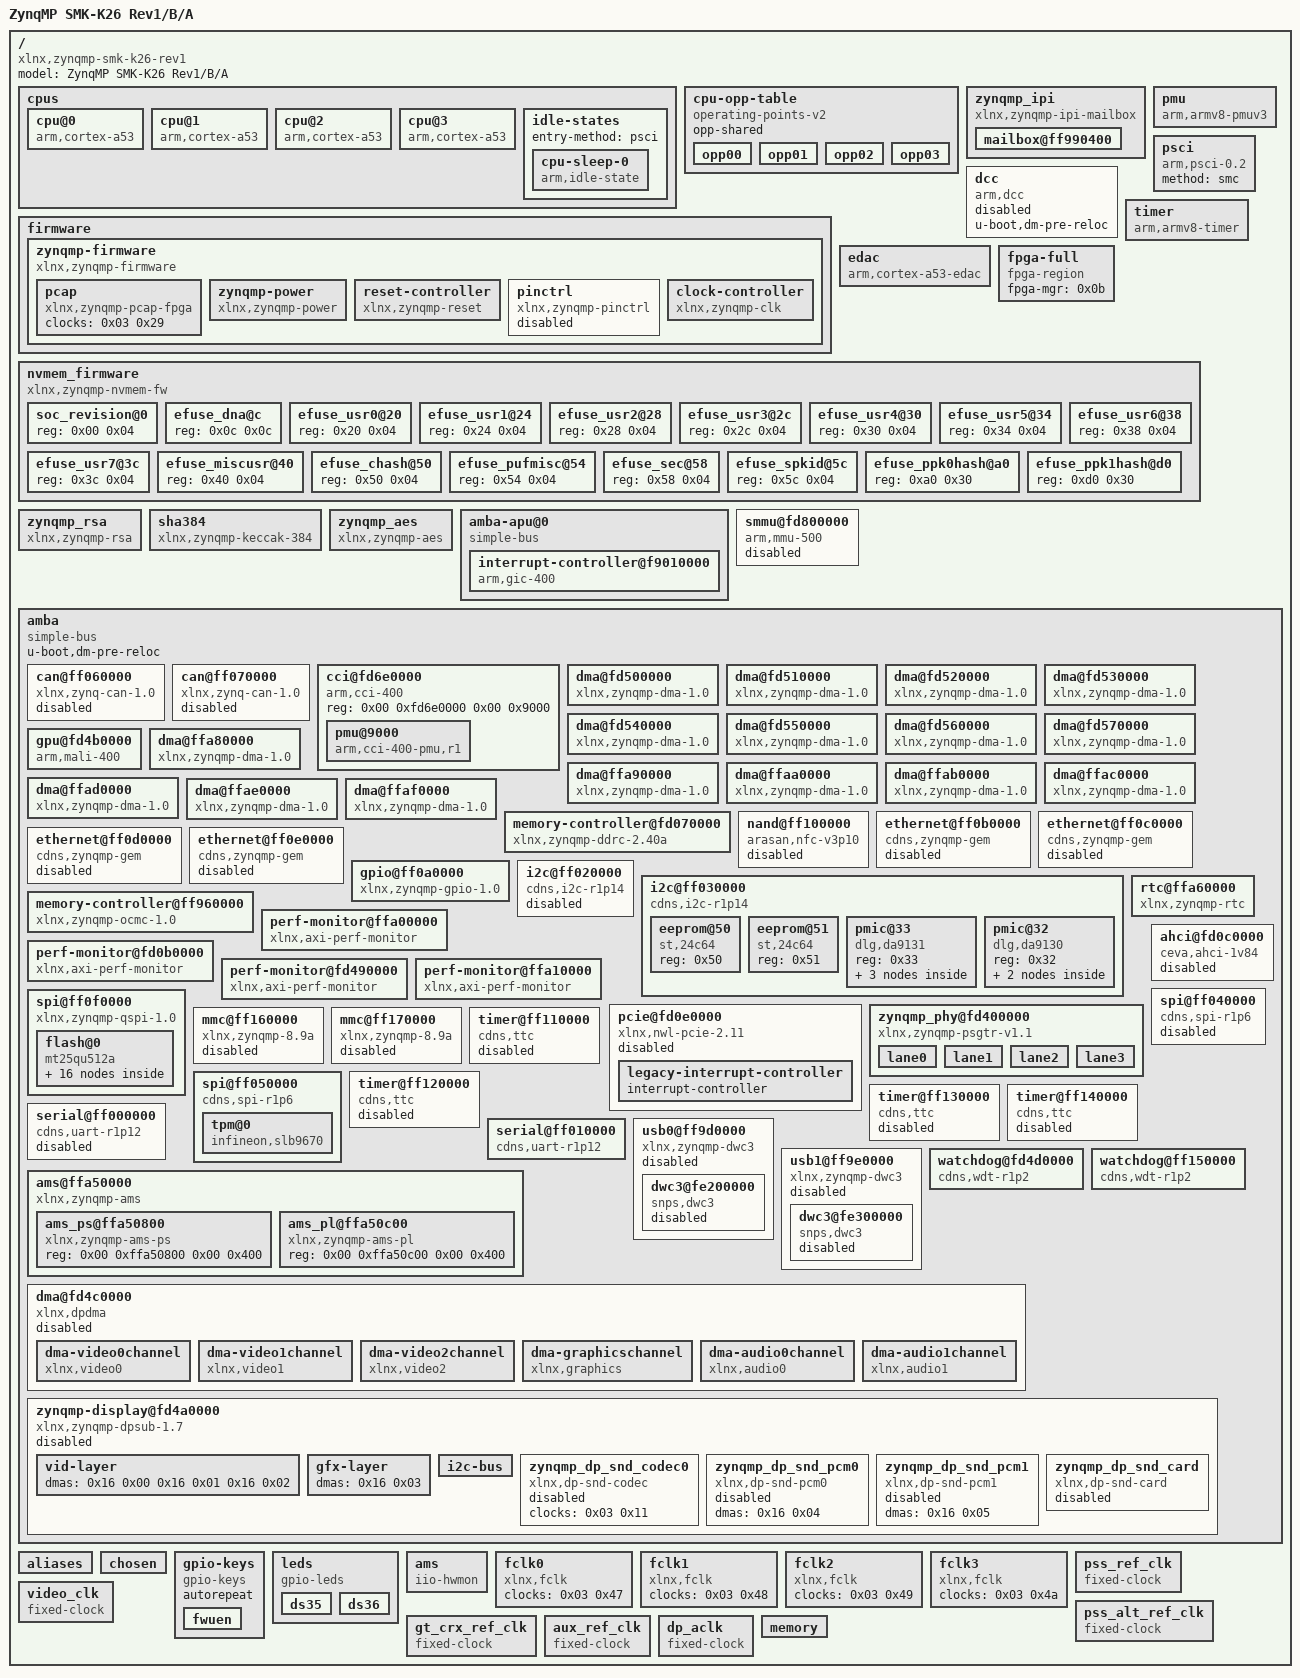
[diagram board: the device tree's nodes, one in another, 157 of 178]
// SPDX-License-Identifier: GPL-2.0
/*
 * KV260 Base Linux DTS
 *
 * (C) Copyright 2021, Xilinx, Inc.
 *
 * amit nagal <amitn@xilinx.com>
 * swagath gadde <swagath.gadde@xilinx.com>
*/

/dts-v1/;

/ {
	compatible = "xlnx,zynqmp-smk-k26-rev1\0xlnx,zynqmp-smk-k26-revB\0xlnx,zynqmp-smk-k26-revA\0xlnx,zynqmp-smk-k26\0xlnx,zynqmp";
	#address-cells = <0x02>;
	#size-cells = <0x02>;
	model = "ZynqMP SMK-K26 Rev1/B/A";

	cpus {
		#address-cells = <0x01>;
		#size-cells = <0x00>;

		cpu@0 {
			compatible = "arm,cortex-a53";
			device_type = "cpu";
			enable-method = "psci";
			operating-points-v2 = <0x01>;
			reg = <0x00>;
			cpu-idle-states = <0x02>;
			clocks = <0x03 0x0a>;
			phandle = <0x1b>;
		};

		cpu@1 {
			compatible = "arm,cortex-a53";
			device_type = "cpu";
			enable-method = "psci";
			reg = <0x01>;
			operating-points-v2 = <0x01>;
			cpu-idle-states = <0x02>;
			phandle = <0x1c>;
		};

		cpu@2 {
			compatible = "arm,cortex-a53";
			device_type = "cpu";
			enable-method = "psci";
			reg = <0x02>;
			operating-points-v2 = <0x01>;
			cpu-idle-states = <0x02>;
			phandle = <0x1d>;
		};

		cpu@3 {
			compatible = "arm,cortex-a53";
			device_type = "cpu";
			enable-method = "psci";
			reg = <0x03>;
			operating-points-v2 = <0x01>;
			cpu-idle-states = <0x02>;
			phandle = <0x1e>;
		};

		idle-states {
			entry-method = "psci";

			cpu-sleep-0 {
				compatible = "arm,idle-state";
				arm,psci-suspend-param = <0x40000000>;
				local-timer-stop;
				entry-latency-us = <0x12c>;
				exit-latency-us = <0x258>;
				min-residency-us = <0x2710>;
				phandle = <0x02>;
			};
		};
	};

	cpu-opp-table {
		compatible = "operating-points-v2";
		opp-shared;
		phandle = <0x01>;

		opp00 {
			opp-hz = <0x00 0x47868bf4>;
			opp-microvolt = <0xf4240>;
			clock-latency-ns = <0x7a120>;
		};

		opp01 {
			opp-hz = <0x00 0x23c345fa>;
			opp-microvolt = <0xf4240>;
			clock-latency-ns = <0x7a120>;
		};

		opp02 {
			opp-hz = <0x00 0x17d783fc>;
			opp-microvolt = <0xf4240>;
			clock-latency-ns = <0x7a120>;
		};

		opp03 {
			opp-hz = <0x00 0x11e1a2fd>;
			opp-microvolt = <0xf4240>;
			clock-latency-ns = <0x7a120>;
		};
	};

	zynqmp_ipi {
		u-boot,dm-pre-reloc;
		compatible = "xlnx,zynqmp-ipi-mailbox";
		interrupt-parent = <0x04>;
		interrupts = <0x00 0x23 0x04>;
		xlnx,ipi-id = <0x00>;
		#address-cells = <0x02>;
		#size-cells = <0x02>;
		ranges;

		mailbox@ff990400 {
			u-boot,dm-pre-reloc;
			reg = <0x00 0xff9905c0 0x00 0x20 0x00 0xff9905e0 0x00 0x20 0x00 0xff990e80 0x00 0x20 0x00 0xff990ea0 0x00 0x20>;
			reg-names = "local_request_region\0local_response_region\0remote_request_region\0remote_response_region";
			#mbox-cells = <0x01>;
			xlnx,ipi-id = <0x04>;
			phandle = <0x05>;
		};
	};

	dcc {
		compatible = "arm,dcc";
		status = "disabled";
		u-boot,dm-pre-reloc;
		phandle = <0x1f>;
	};

	pmu {
		compatible = "arm,armv8-pmuv3";
		interrupt-parent = <0x04>;
		interrupts = <0x00 0x8f 0x04 0x00 0x90 0x04 0x00 0x91 0x04 0x00 0x92 0x04>;
	};

	psci {
		compatible = "arm,psci-0.2";
		method = "smc";
	};

	firmware {

		zynqmp-firmware {
			compatible = "xlnx,zynqmp-firmware";
			u-boot,dm-pre-reloc;
			method = "smc";
			#power-domain-cells = <0x01>;
			phandle = <0x0c>;

			pcap {
				compatible = "xlnx,zynqmp-pcap-fpga";
				clock-names = "ref_clk";
				clocks = <0x03 0x29>;
				phandle = <0x0b>;
			};

			zynqmp-power {
				u-boot,dm-pre-reloc;
				compatible = "xlnx,zynqmp-power";
				interrupt-parent = <0x04>;
				interrupts = <0x00 0x23 0x04>;
				mboxes = <0x05 0x00 0x05 0x01>;
				mbox-names = "tx\0rx";
				phandle = <0x20>;
			};

			reset-controller {
				compatible = "xlnx,zynqmp-reset";
				#reset-cells = <0x01>;
				phandle = <0x12>;
			};

			pinctrl {
				compatible = "xlnx,zynqmp-pinctrl";
				status = "disabled";
				phandle = <0x21>;
			};

			clock-controller {
				u-boot,dm-pre-reloc;
				#clock-cells = <0x01>;
				compatible = "xlnx,zynqmp-clk";
				clocks = <0x06 0x07 0x08 0x09 0x0a>;
				clock-names = "pss_ref_clk\0video_clk\0pss_alt_ref_clk\0aux_ref_clk\0gt_crx_ref_clk";
				phandle = <0x03>;
			};
		};
	};

	timer {
		compatible = "arm,armv8-timer";
		interrupt-parent = <0x04>;
		interrupts = <0x01 0x0d 0xf08 0x01 0x0e 0xf08 0x01 0x0b 0xf08 0x01 0x0a 0xf08>;
	};

	edac {
		compatible = "arm,cortex-a53-edac";
	};

	fpga-full {
		compatible = "fpga-region";
		fpga-mgr = <0x0b>;
		#address-cells = <0x02>;
		#size-cells = <0x02>;
		ranges;
		phandle = <0x22>;
	};

	nvmem_firmware {
		compatible = "xlnx,zynqmp-nvmem-fw";
		#address-cells = <0x01>;
		#size-cells = <0x01>;

		soc_revision@0 {
			reg = <0x00 0x04>;
			phandle = <0x11>;
		};

		efuse_dna@c {
			reg = <0x0c 0x0c>;
			phandle = <0x23>;
		};

		efuse_usr0@20 {
			reg = <0x20 0x04>;
			phandle = <0x24>;
		};

		efuse_usr1@24 {
			reg = <0x24 0x04>;
			phandle = <0x25>;
		};

		efuse_usr2@28 {
			reg = <0x28 0x04>;
			phandle = <0x26>;
		};

		efuse_usr3@2c {
			reg = <0x2c 0x04>;
			phandle = <0x27>;
		};

		efuse_usr4@30 {
			reg = <0x30 0x04>;
			phandle = <0x28>;
		};

		efuse_usr5@34 {
			reg = <0x34 0x04>;
			phandle = <0x29>;
		};

		efuse_usr6@38 {
			reg = <0x38 0x04>;
			phandle = <0x2a>;
		};

		efuse_usr7@3c {
			reg = <0x3c 0x04>;
			phandle = <0x2b>;
		};

		efuse_miscusr@40 {
			reg = <0x40 0x04>;
			phandle = <0x2c>;
		};

		efuse_chash@50 {
			reg = <0x50 0x04>;
			phandle = <0x2d>;
		};

		efuse_pufmisc@54 {
			reg = <0x54 0x04>;
			phandle = <0x2e>;
		};

		efuse_sec@58 {
			reg = <0x58 0x04>;
			phandle = <0x2f>;
		};

		efuse_spkid@5c {
			reg = <0x5c 0x04>;
			phandle = <0x30>;
		};

		efuse_ppk0hash@a0 {
			reg = <0xa0 0x30>;
			phandle = <0x31>;
		};

		efuse_ppk1hash@d0 {
			reg = <0xd0 0x30>;
			phandle = <0x32>;
		};
	};

	zynqmp_rsa {
		compatible = "xlnx,zynqmp-rsa";
		phandle = <0x33>;
	};

	sha384 {
		compatible = "xlnx,zynqmp-keccak-384";
		phandle = <0x34>;
	};

	zynqmp_aes {
		compatible = "xlnx,zynqmp-aes";
		phandle = <0x35>;
	};

	amba-apu@0 {
		compatible = "simple-bus";
		#address-cells = <0x02>;
		#size-cells = <0x01>;
		ranges = <0x00 0x00 0x00 0x00 0xffffffff>;
		phandle = <0x36>;

		interrupt-controller@f9010000 {
			compatible = "arm,gic-400";
			#interrupt-cells = <0x03>;
			reg = <0x00 0xf9010000 0x10000 0x00 0xf9020000 0x20000 0x00 0xf9040000 0x20000 0x00 0xf9060000 0x20000>;
			interrupt-controller;
			interrupt-parent = <0x04>;
			interrupts = <0x01 0x09 0xf04>;
			num_cpus = <0x02>;
			num_interrupts = <0x60>;
			phandle = <0x04>;
		};
	};

	smmu@fd800000 {
		compatible = "arm,mmu-500";
		reg = <0x00 0xfd800000 0x00 0x20000>;
		#iommu-cells = <0x01>;
		status = "disabled";
		#global-interrupts = <0x01>;
		interrupt-parent = <0x04>;
		interrupts = <0x00 0x9b 0x04 0x00 0x9b 0x04 0x00 0x9b 0x04 0x00 0x9b 0x04 0x00 0x9b 0x04 0x00 0x9b 0x04 0x00 0x9b 0x04 0x00 0x9b 0x04 0x00 0x9b 0x04 0x00 0x9b 0x04 0x00 0x9b 0x04 0x00 0x9b 0x04 0x00 0x9b 0x04 0x00 0x9b 0x04 0x00 0x9b 0x04 0x00 0x9b 0x04 0x00 0x9b 0x04>;
		phandle = <0x0d>;
	};

	amba {
		compatible = "simple-bus";
		u-boot,dm-pre-reloc;
		#address-cells = <0x02>;
		#size-cells = <0x02>;
		ranges;
		phandle = <0x37>;

		can@ff060000 {
			compatible = "xlnx,zynq-can-1.0";
			status = "disabled";
			clock-names = "can_clk\0pclk";
			reg = <0x00 0xff060000 0x00 0x1000>;
			interrupts = <0x00 0x17 0x04>;
			interrupt-parent = <0x04>;
			tx-fifo-depth = <0x40>;
			rx-fifo-depth = <0x40>;
			power-domains = <0x0c 0x2f>;
			clocks = <0x03 0x3f 0x03 0x1f>;
			phandle = <0x38>;
		};

		can@ff070000 {
			compatible = "xlnx,zynq-can-1.0";
			status = "disabled";
			clock-names = "can_clk\0pclk";
			reg = <0x00 0xff070000 0x00 0x1000>;
			interrupts = <0x00 0x18 0x04>;
			interrupt-parent = <0x04>;
			tx-fifo-depth = <0x40>;
			rx-fifo-depth = <0x40>;
			power-domains = <0x0c 0x30>;
			clocks = <0x03 0x40 0x03 0x1f>;
			phandle = <0x39>;
		};

		cci@fd6e0000 {
			compatible = "arm,cci-400";
			status = "okay";
			reg = <0x00 0xfd6e0000 0x00 0x9000>;
			ranges = <0x00 0x00 0xfd6e0000 0x10000>;
			#address-cells = <0x01>;
			#size-cells = <0x01>;
			phandle = <0x3a>;

			pmu@9000 {
				compatible = "arm,cci-400-pmu,r1";
				reg = <0x9000 0x5000>;
				interrupt-parent = <0x04>;
				interrupts = <0x00 0x7b 0x04 0x00 0x7b 0x04 0x00 0x7b 0x04 0x00 0x7b 0x04 0x00 0x7b 0x04>;
			};
		};

		dma@fd500000 {
			status = "okay";
			compatible = "xlnx,zynqmp-dma-1.0";
			reg = <0x00 0xfd500000 0x00 0x1000>;
			interrupt-parent = <0x04>;
			interrupts = <0x00 0x7c 0x04>;
			clock-names = "clk_main\0clk_apb";
			xlnx,bus-width = <0x80>;
			#stream-id-cells = <0x01>;
			iommus = <0x0d 0x14e8>;
			power-domains = <0x0c 0x2a>;
			clocks = <0x03 0x13 0x03 0x1f>;
			phandle = <0x3b>;
		};

		dma@fd510000 {
			status = "okay";
			compatible = "xlnx,zynqmp-dma-1.0";
			reg = <0x00 0xfd510000 0x00 0x1000>;
			interrupt-parent = <0x04>;
			interrupts = <0x00 0x7d 0x04>;
			clock-names = "clk_main\0clk_apb";
			xlnx,bus-width = <0x80>;
			#stream-id-cells = <0x01>;
			iommus = <0x0d 0x14e9>;
			power-domains = <0x0c 0x2a>;
			clocks = <0x03 0x13 0x03 0x1f>;
			phandle = <0x3c>;
		};

		dma@fd520000 {
			status = "okay";
			compatible = "xlnx,zynqmp-dma-1.0";
			reg = <0x00 0xfd520000 0x00 0x1000>;
			interrupt-parent = <0x04>;
			interrupts = <0x00 0x7e 0x04>;
			clock-names = "clk_main\0clk_apb";
			xlnx,bus-width = <0x80>;
			#stream-id-cells = <0x01>;
			iommus = <0x0d 0x14ea>;
			power-domains = <0x0c 0x2a>;
			clocks = <0x03 0x13 0x03 0x1f>;
			phandle = <0x3d>;
		};

		dma@fd530000 {
			status = "okay";
			compatible = "xlnx,zynqmp-dma-1.0";
			reg = <0x00 0xfd530000 0x00 0x1000>;
			interrupt-parent = <0x04>;
			interrupts = <0x00 0x7f 0x04>;
			clock-names = "clk_main\0clk_apb";
			xlnx,bus-width = <0x80>;
			#stream-id-cells = <0x01>;
			iommus = <0x0d 0x14eb>;
			power-domains = <0x0c 0x2a>;
			clocks = <0x03 0x13 0x03 0x1f>;
			phandle = <0x3e>;
		};

		dma@fd540000 {
			status = "okay";
			compatible = "xlnx,zynqmp-dma-1.0";
			reg = <0x00 0xfd540000 0x00 0x1000>;
			interrupt-parent = <0x04>;
			interrupts = <0x00 0x80 0x04>;
			clock-names = "clk_main\0clk_apb";
			xlnx,bus-width = <0x80>;
			#stream-id-cells = <0x01>;
			iommus = <0x0d 0x14ec>;
			power-domains = <0x0c 0x2a>;
			clocks = <0x03 0x13 0x03 0x1f>;
			phandle = <0x3f>;
		};

		dma@fd550000 {
			status = "okay";
			compatible = "xlnx,zynqmp-dma-1.0";
			reg = <0x00 0xfd550000 0x00 0x1000>;
			interrupt-parent = <0x04>;
			interrupts = <0x00 0x81 0x04>;
			clock-names = "clk_main\0clk_apb";
			xlnx,bus-width = <0x80>;
			#stream-id-cells = <0x01>;
			iommus = <0x0d 0x14ed>;
			power-domains = <0x0c 0x2a>;
			clocks = <0x03 0x13 0x03 0x1f>;
			phandle = <0x40>;
		};

		dma@fd560000 {
			status = "okay";
			compatible = "xlnx,zynqmp-dma-1.0";
			reg = <0x00 0xfd560000 0x00 0x1000>;
			interrupt-parent = <0x04>;
			interrupts = <0x00 0x82 0x04>;
			clock-names = "clk_main\0clk_apb";
			xlnx,bus-width = <0x80>;
			#stream-id-cells = <0x01>;
			iommus = <0x0d 0x14ee>;
			power-domains = <0x0c 0x2a>;
			clocks = <0x03 0x13 0x03 0x1f>;
			phandle = <0x41>;
		};

		dma@fd570000 {
			status = "okay";
			compatible = "xlnx,zynqmp-dma-1.0";
			reg = <0x00 0xfd570000 0x00 0x1000>;
			interrupt-parent = <0x04>;
			interrupts = <0x00 0x83 0x04>;
			clock-names = "clk_main\0clk_apb";
			xlnx,bus-width = <0x80>;
			#stream-id-cells = <0x01>;
			iommus = <0x0d 0x14ef>;
			power-domains = <0x0c 0x2a>;
			clocks = <0x03 0x13 0x03 0x1f>;
			phandle = <0x42>;
		};

		gpu@fd4b0000 {
			status = "okay";
			compatible = "arm,mali-400\0arm,mali-utgard";
			reg = <0x00 0xfd4b0000 0x00 0x10000>;
			interrupt-parent = <0x04>;
			interrupts = <0x00 0x84 0x04 0x00 0x84 0x04 0x00 0x84 0x04 0x00 0x84 0x04 0x00 0x84 0x04 0x00 0x84 0x04>;
			interrupt-names = "IRQGP\0IRQGPMMU\0IRQPP0\0IRQPPMMU0\0IRQPP1\0IRQPPMMU1";
			clock-names = "gpu\0gpu_pp0\0gpu_pp1";
			power-domains = <0x0c 0x3a>;
			clocks = <0x03 0x18 0x03 0x19 0x03 0x1a>;
			xlnx,tz-nonsecure = <0x01>;
			phandle = <0x43>;
		};

		dma@ffa80000 {
			status = "okay";
			compatible = "xlnx,zynqmp-dma-1.0";
			reg = <0x00 0xffa80000 0x00 0x1000>;
			interrupt-parent = <0x04>;
			interrupts = <0x00 0x4d 0x04>;
			clock-names = "clk_main\0clk_apb";
			xlnx,bus-width = <0x40>;
			#stream-id-cells = <0x01>;
			power-domains = <0x0c 0x2b>;
			clocks = <0x03 0x44 0x03 0x1f>;
			phandle = <0x44>;
		};

		dma@ffa90000 {
			status = "okay";
			compatible = "xlnx,zynqmp-dma-1.0";
			reg = <0x00 0xffa90000 0x00 0x1000>;
			interrupt-parent = <0x04>;
			interrupts = <0x00 0x4e 0x04>;
			clock-names = "clk_main\0clk_apb";
			xlnx,bus-width = <0x40>;
			#stream-id-cells = <0x01>;
			power-domains = <0x0c 0x2b>;
			clocks = <0x03 0x44 0x03 0x1f>;
			phandle = <0x45>;
		};

		dma@ffaa0000 {
			status = "okay";
			compatible = "xlnx,zynqmp-dma-1.0";
			reg = <0x00 0xffaa0000 0x00 0x1000>;
			interrupt-parent = <0x04>;
			interrupts = <0x00 0x4f 0x04>;
			clock-names = "clk_main\0clk_apb";
			xlnx,bus-width = <0x40>;
			#stream-id-cells = <0x01>;
			power-domains = <0x0c 0x2b>;
			clocks = <0x03 0x44 0x03 0x1f>;
			phandle = <0x46>;
		};

		dma@ffab0000 {
			status = "okay";
			compatible = "xlnx,zynqmp-dma-1.0";
			reg = <0x00 0xffab0000 0x00 0x1000>;
			interrupt-parent = <0x04>;
			interrupts = <0x00 0x50 0x04>;
			clock-names = "clk_main\0clk_apb";
			xlnx,bus-width = <0x40>;
			#stream-id-cells = <0x01>;
			power-domains = <0x0c 0x2b>;
			clocks = <0x03 0x44 0x03 0x1f>;
			phandle = <0x47>;
		};

		dma@ffac0000 {
			status = "okay";
			compatible = "xlnx,zynqmp-dma-1.0";
			reg = <0x00 0xffac0000 0x00 0x1000>;
			interrupt-parent = <0x04>;
			interrupts = <0x00 0x51 0x04>;
			clock-names = "clk_main\0clk_apb";
			xlnx,bus-width = <0x40>;
			#stream-id-cells = <0x01>;
			power-domains = <0x0c 0x2b>;
			clocks = <0x03 0x44 0x03 0x1f>;
			phandle = <0x48>;
		};

		dma@ffad0000 {
			status = "okay";
			compatible = "xlnx,zynqmp-dma-1.0";
			reg = <0x00 0xffad0000 0x00 0x1000>;
			interrupt-parent = <0x04>;
			interrupts = <0x00 0x52 0x04>;
			clock-names = "clk_main\0clk_apb";
			xlnx,bus-width = <0x40>;
			#stream-id-cells = <0x01>;
			power-domains = <0x0c 0x2b>;
			clocks = <0x03 0x44 0x03 0x1f>;
			phandle = <0x49>;
		};

		dma@ffae0000 {
			status = "okay";
			compatible = "xlnx,zynqmp-dma-1.0";
			reg = <0x00 0xffae0000 0x00 0x1000>;
			interrupt-parent = <0x04>;
			interrupts = <0x00 0x53 0x04>;
			clock-names = "clk_main\0clk_apb";
			xlnx,bus-width = <0x40>;
			#stream-id-cells = <0x01>;
			power-domains = <0x0c 0x2b>;
			clocks = <0x03 0x44 0x03 0x1f>;
			phandle = <0x4a>;
		};

		dma@ffaf0000 {
			status = "okay";
			compatible = "xlnx,zynqmp-dma-1.0";
			reg = <0x00 0xffaf0000 0x00 0x1000>;
			interrupt-parent = <0x04>;
			interrupts = <0x00 0x54 0x04>;
			clock-names = "clk_main\0clk_apb";
			xlnx,bus-width = <0x40>;
			#stream-id-cells = <0x01>;
			power-domains = <0x0c 0x2b>;
			clocks = <0x03 0x44 0x03 0x1f>;
			phandle = <0x4b>;
		};

		memory-controller@fd070000 {
			compatible = "xlnx,zynqmp-ddrc-2.40a";
			reg = <0x00 0xfd070000 0x00 0x30000>;
			interrupt-parent = <0x04>;
			interrupts = <0x00 0x70 0x04>;
			phandle = <0x4c>;
		};

		nand@ff100000 {
			compatible = "arasan,nfc-v3p10";
			status = "disabled";
			reg = <0x00 0xff100000 0x00 0x1000>;
			clock-names = "clk_sys\0clk_flash";
			interrupt-parent = <0x04>;
			interrupts = <0x00 0x0e 0x04>;
			#address-cells = <0x01>;
			#size-cells = <0x00>;
			#stream-id-cells = <0x01>;
			iommus = <0x0d 0x872>;
			power-domains = <0x0c 0x2c>;
			clocks = <0x03 0x3c 0x03 0x1f>;
			phandle = <0x4d>;
		};

		ethernet@ff0b0000 {
			compatible = "cdns,zynqmp-gem\0cdns,gem";
			status = "disabled";
			interrupt-parent = <0x04>;
			interrupts = <0x00 0x39 0x04 0x00 0x39 0x04>;
			reg = <0x00 0xff0b0000 0x00 0x1000>;
			clock-names = "pclk\0hclk\0tx_clk\0rx_clk\0tsu_clk";
			#address-cells = <0x01>;
			#size-cells = <0x00>;
			#stream-id-cells = <0x01>;
			iommus = <0x0d 0x874>;
			power-domains = <0x0c 0x1d>;
			clocks = <0x03 0x1f 0x03 0x68 0x03 0x2d 0x03 0x31 0x03 0x2c>;
			phandle = <0x4e>;
		};

		ethernet@ff0c0000 {
			compatible = "cdns,zynqmp-gem\0cdns,gem";
			status = "disabled";
			interrupt-parent = <0x04>;
			interrupts = <0x00 0x3b 0x04 0x00 0x3b 0x04>;
			reg = <0x00 0xff0c0000 0x00 0x1000>;
			clock-names = "pclk\0hclk\0tx_clk\0rx_clk\0tsu_clk";
			#address-cells = <0x01>;
			#size-cells = <0x00>;
			#stream-id-cells = <0x01>;
			iommus = <0x0d 0x875>;
			power-domains = <0x0c 0x1e>;
			clocks = <0x03 0x1f 0x03 0x69 0x03 0x2e 0x03 0x32 0x03 0x2c>;
			phandle = <0x4f>;
		};

		ethernet@ff0d0000 {
			compatible = "cdns,zynqmp-gem\0cdns,gem";
			status = "disabled";
			interrupt-parent = <0x04>;
			interrupts = <0x00 0x3d 0x04 0x00 0x3d 0x04>;
			reg = <0x00 0xff0d0000 0x00 0x1000>;
			clock-names = "pclk\0hclk\0tx_clk\0rx_clk\0tsu_clk";
			#address-cells = <0x01>;
			#size-cells = <0x00>;
			#stream-id-cells = <0x01>;
			iommus = <0x0d 0x876>;
			power-domains = <0x0c 0x1f>;
			clocks = <0x03 0x1f 0x03 0x6a 0x03 0x2f 0x03 0x33 0x03 0x2c>;
			phandle = <0x50>;
		};

		ethernet@ff0e0000 {
			compatible = "cdns,zynqmp-gem\0cdns,gem";
			status = "disabled";
			interrupt-parent = <0x04>;
			interrupts = <0x00 0x3f 0x04 0x00 0x3f 0x04>;
			reg = <0x00 0xff0e0000 0x00 0x1000>;
			clock-names = "pclk\0hclk\0tx_clk\0rx_clk\0tsu_clk";
			#address-cells = <0x01>;
			#size-cells = <0x00>;
			#stream-id-cells = <0x01>;
			iommus = <0x0d 0x877>;
			power-domains = <0x0c 0x20>;
			clocks = <0x03 0x1f 0x03 0x6b 0x03 0x30 0x03 0x34 0x03 0x2c>;
			phy-mode = "rgmii-id";
			xlnx,ptp-enet-clock = <0x00>;
			local-mac-address = [00 0a 35 00 22 01];
			phandle = <0x51>;
		};

		gpio@ff0a0000 {
			compatible = "xlnx,zynqmp-gpio-1.0";
			status = "okay";
			#gpio-cells = <0x02>;
			gpio-controller;
			interrupt-parent = <0x04>;
			interrupts = <0x00 0x10 0x04>;
			interrupt-controller;
			#interrupt-cells = <0x02>;
			reg = <0x00 0xff0a0000 0x00 0x1000>;
			power-domains = <0x0c 0x2e>;
			gpio-line-names = "QSPI_CLK\0QSPI_DQ1\0QSPI_DQ2\0QSPI_DQ3\0QSPI_DQ0\0QSPI_CS_B\0SPI_CLK\0LED1\0LED2\0SPI_CS_B\0SPI_MISO\0SPI_MOSI\0FWUEN\0EMMC_DAT0\0EMMC_DAT1\0EMMC_DAT2\0EMMC_DAT3\0EMMC_DAT4\0EMMC_DAT5\0EMMC_DAT6\0EMMC_DAT7\0EMMC_CMD\0EMMC_CLK\0EMMC_RST\0I2C1_SCL\0I2C1_SDA\0\0\0\0\0\0\0\0\0\0\0\0\0\0\0\0\0\0\0\0\0\0\0\0\0\0\0\0\0\0\0\0\0\0\0\0\0\0\0\0\0\0\0\0\0\0\0\0\0\0\0\0\0\0\0\0\0\0\0\0\0\0\0\0\0\0\0\0\0\0\0\0\0\0\0\0\0\0\0\0\0\0\0\0\0\0\0\0\0\0\0\0\0\0\0\0\0\0\0\0\0\0\0\0\0\0\0\0\0\0\0\0\0\0\0\0\0\0\0\0\0\0\0\0\0\0\0\0\0\0\0\0\0\0\0\0\0\0\0\0\0\0\0\0\0\0\0\0";
			clocks = <0x03 0x1f>;
			emio-gpio-width = <0x20>;
			gpio-mask-high = <0x00>;
			gpio-mask-low = <0x5600>;
			phandle = <0x0e>;
		};

		i2c@ff020000 {
			compatible = "cdns,i2c-r1p14\0cdns,i2c-r1p10";
			status = "disabled";
			interrupt-parent = <0x04>;
			interrupts = <0x00 0x11 0x04>;
			reg = <0x00 0xff020000 0x00 0x1000>;
			#address-cells = <0x01>;
			#size-cells = <0x00>;
			power-domains = <0x0c 0x25>;
			clocks = <0x03 0x3d>;
			phandle = <0x52>;
		};

		i2c@ff030000 {
			compatible = "cdns,i2c-r1p14\0cdns,i2c-r1p10";
			status = "okay";
			interrupt-parent = <0x04>;
			interrupts = <0x00 0x12 0x04>;
			reg = <0x00 0xff030000 0x00 0x1000>;
			#address-cells = <0x01>;
			#size-cells = <0x00>;
			power-domains = <0x0c 0x26>;
			clock-frequency = <0x61a80>;
			scl-gpios = <0x0e 0x18 0x00>;
			sda-gpios = <0x0e 0x19 0x00>;
			clocks = <0x03 0x3e>;
			phandle = <0x53>;

			eeprom@50 {
				compatible = "st,24c64\0atmel,24c64";
				reg = <0x50>;
				phandle = <0x54>;
			};

			eeprom@51 {
				compatible = "st,24c64\0atmel,24c64";
				reg = <0x51>;
				phandle = <0x55>;
			};

			pmic@33 {
				compatible = "dlg,da9131";
				reg = <0x33>;
				phandle = <0x56>;

				regulators {

					buck1 {
						regulator-name = "da9131_buck1";
						regulator-boot-on;
						regulator-always-on;
						phandle = <0x57>;
					};

					buck2 {
						regulator-name = "da9131_buck2";
						regulator-boot-on;
						regulator-always-on;
						phandle = <0x58>;
					};
				};
			};

			pmic@32 {
				compatible = "dlg,da9130";
				reg = <0x32>;
				phandle = <0x59>;

				regulators {

					buck1 {
						regulator-name = "da9130_buck1";
						regulator-boot-on;
						regulator-always-on;
						phandle = <0x5a>;
					};
				};
			};
		};

		memory-controller@ff960000 {
			compatible = "xlnx,zynqmp-ocmc-1.0";
			reg = <0x00 0xff960000 0x00 0x1000>;
			interrupt-parent = <0x04>;
			interrupts = <0x00 0x0a 0x04>;
			phandle = <0x5b>;
		};

		perf-monitor@ffa00000 {
			compatible = "xlnx,axi-perf-monitor";
			reg = <0x00 0xffa00000 0x00 0x10000>;
			interrupts = <0x00 0x19 0x04>;
			interrupt-parent = <0x04>;
			xlnx,enable-profile = <0x00>;
			xlnx,enable-trace = <0x00>;
			xlnx,num-monitor-slots = <0x01>;
			xlnx,enable-event-count = <0x01>;
			xlnx,enable-event-log = <0x01>;
			xlnx,have-sampled-metric-cnt = <0x01>;
			xlnx,num-of-counters = <0x08>;
			xlnx,metric-count-width = <0x20>;
			xlnx,metrics-sample-count-width = <0x20>;
			xlnx,global-count-width = <0x20>;
			xlnx,metric-count-scale = <0x01>;
			clocks = <0x03 0x1f>;
			phandle = <0x5c>;
		};

		perf-monitor@fd0b0000 {
			compatible = "xlnx,axi-perf-monitor";
			reg = <0x00 0xfd0b0000 0x00 0x10000>;
			interrupts = <0x00 0x7b 0x04>;
			interrupt-parent = <0x04>;
			xlnx,enable-profile = <0x00>;
			xlnx,enable-trace = <0x00>;
			xlnx,num-monitor-slots = <0x06>;
			xlnx,enable-event-count = <0x01>;
			xlnx,enable-event-log = <0x00>;
			xlnx,have-sampled-metric-cnt = <0x01>;
			xlnx,num-of-counters = <0x0a>;
			xlnx,metric-count-width = <0x20>;
			xlnx,metrics-sample-count-width = <0x20>;
			xlnx,global-count-width = <0x20>;
			xlnx,metric-count-scale = <0x01>;
			clocks = <0x03 0x1c>;
			phandle = <0x5d>;
		};

		perf-monitor@fd490000 {
			compatible = "xlnx,axi-perf-monitor";
			reg = <0x00 0xfd490000 0x00 0x10000>;
			interrupts = <0x00 0x7b 0x04>;
			interrupt-parent = <0x04>;
			xlnx,enable-profile = <0x00>;
			xlnx,enable-trace = <0x00>;
			xlnx,num-monitor-slots = <0x01>;
			xlnx,enable-event-count = <0x01>;
			xlnx,enable-event-log = <0x00>;
			xlnx,have-sampled-metric-cnt = <0x01>;
			xlnx,num-of-counters = <0x08>;
			xlnx,metric-count-width = <0x20>;
			xlnx,metrics-sample-count-width = <0x20>;
			xlnx,global-count-width = <0x20>;
			xlnx,metric-count-scale = <0x01>;
			clocks = <0x03 0x1c>;
			phandle = <0x5e>;
		};

		perf-monitor@ffa10000 {
			compatible = "xlnx,axi-perf-monitor";
			reg = <0x00 0xffa10000 0x00 0x10000>;
			interrupts = <0x00 0x19 0x04>;
			interrupt-parent = <0x04>;
			xlnx,enable-profile = <0x00>;
			xlnx,enable-trace = <0x00>;
			xlnx,num-monitor-slots = <0x01>;
			xlnx,enable-event-count = <0x01>;
			xlnx,enable-event-log = <0x01>;
			xlnx,have-sampled-metric-cnt = <0x01>;
			xlnx,num-of-counters = <0x08>;
			xlnx,metric-count-width = <0x20>;
			xlnx,metrics-sample-count-width = <0x20>;
			xlnx,global-count-width = <0x20>;
			xlnx,metric-count-scale = <0x01>;
			clocks = <0x03 0x1f>;
			phandle = <0x5f>;
		};

		pcie@fd0e0000 {
			compatible = "xlnx,nwl-pcie-2.11";
			status = "disabled";
			#address-cells = <0x03>;
			#size-cells = <0x02>;
			#interrupt-cells = <0x01>;
			msi-controller;
			device_type = "pci";
			interrupt-parent = <0x04>;
			interrupts = <0x00 0x76 0x04 0x00 0x75 0x04 0x00 0x74 0x04 0x00 0x73 0x04 0x00 0x72 0x04>;
			interrupt-names = "misc\0dummy\0intx\0msi1\0msi0";
			msi-parent = <0x0f>;
			reg = <0x00 0xfd0e0000 0x00 0x1000 0x00 0xfd480000 0x00 0x1000 0x80 0x00 0x00 0x1000000>;
			reg-names = "breg\0pcireg\0cfg";
			ranges = <0x2000000 0x00 0xe0000000 0x00 0xe0000000 0x00 0x10000000 0x43000000 0x06 0x00 0x06 0x00 0x02 0x00>;
			interrupt-map-mask = <0x00 0x00 0x00 0x07>;
			bus-range = <0x00 0xff>;
			interrupt-map = <0x00 0x00 0x00 0x01 0x10 0x01 0x00 0x00 0x00 0x02 0x10 0x02 0x00 0x00 0x00 0x03 0x10 0x03 0x00 0x00 0x00 0x04 0x10 0x04>;
			power-domains = <0x0c 0x3b>;
			clocks = <0x03 0x17>;
			phandle = <0x0f>;

			legacy-interrupt-controller {
				interrupt-controller;
				#address-cells = <0x00>;
				#interrupt-cells = <0x01>;
				phandle = <0x10>;
			};
		};

		spi@ff0f0000 {
			u-boot,dm-pre-reloc;
			compatible = "xlnx,zynqmp-qspi-1.0";
			status = "okay";
			clock-names = "ref_clk\0pclk";
			interrupts = <0x00 0x0f 0x04>;
			interrupt-parent = <0x04>;
			num-cs = <0x01>;
			reg = <0x00 0xff0f0000 0x00 0x1000 0x00 0xc0000000 0x00 0x8000000>;
			#address-cells = <0x01>;
			#size-cells = <0x00>;
			#stream-id-cells = <0x01>;
			iommus = <0x0d 0x873>;
			power-domains = <0x0c 0x2d>;
			clocks = <0x03 0x35 0x03 0x1f>;
			is-dual = <0x00>;
			spi-rx-bus-width = <0x04>;
			spi-tx-bus-width = <0x04>;
			phandle = <0x60>;

			flash@0 {
				compatible = "mt25qu512a\0jedec,spi-nor";
				#address-cells = <0x01>;
				#size-cells = <0x01>;
				reg = <0x00>;
				spi-tx-bus-width = <0x01>;
				spi-rx-bus-width = <0x04>;
				spi-max-frequency = <0x2625a00>;

				partition@0 {
					label = "Image Selector";
					reg = <0x00 0x80000>;
					read-only;
					lock;
				};

				partition@80000 {
					label = "Image Selector Golden";
					reg = <0x80000 0x80000>;
					read-only;
					lock;
				};

				partition@100000 {
					label = "Persistent Register";
					reg = <0x100000 0x20000>;
				};

				partition@120000 {
					label = "Persistent Register Backup";
					reg = <0x120000 0x20000>;
				};

				partition@140000 {
					label = "Open_1";
					reg = <0x140000 0xc0000>;
				};

				partition@200000 {
					label = "Image A (FSBL, PMU, ATF, U-Boot)";
					reg = <0x200000 0xd00000>;
				};

				partition@f00000 {
					label = "ImgSel Image A Catch";
					reg = <0xf00000 0x80000>;
					read-only;
					lock;
				};

				partition@f80000 {
					label = "Image B (FSBL, PMU, ATF, U-Boot)";
					reg = <0xf80000 0xd00000>;
				};

				partition@1c80000 {
					label = "ImgSel Image B Catch";
					reg = <0x1c80000 0x80000>;
					read-only;
					lock;
				};

				partition@1d00000 {
					label = "Open_2";
					reg = <0x1d00000 0x100000>;
				};

				partition@1e00000 {
					label = "Recovery Image";
					reg = <0x1e00000 0x200000>;
					read-only;
					lock;
				};

				partition@2000000 {
					label = "Recovery Image Backup";
					reg = <0x2000000 0x200000>;
					read-only;
					lock;
				};

				partition@2200000 {
					label = "U-Boot storage variables";
					reg = <0x2200000 0x20000>;
				};

				partition@2220000 {
					label = "U-Boot storage variables backup";
					reg = <0x2220000 0x20000>;
				};

				partition@2240000 {
					label = "SHA256";
					reg = <0x2240000 0x10000>;
					read-only;
					lock;
				};

				partition@2250000 {
					label = "User";
					reg = <0x2250000 0x1db0000>;
				};
			};
		};

		rtc@ffa60000 {
			compatible = "xlnx,zynqmp-rtc";
			status = "okay";
			reg = <0x00 0xffa60000 0x00 0x100>;
			interrupt-parent = <0x04>;
			interrupts = <0x00 0x1a 0x04 0x00 0x1b 0x04>;
			interrupt-names = "alarm\0sec";
			calibration = <0x8000>;
			phandle = <0x61>;
		};

		zynqmp_phy@fd400000 {
			compatible = "xlnx,zynqmp-psgtr-v1.1";
			status = "okay";
			reg = <0x00 0xfd400000 0x00 0x40000 0x00 0xfd3d0000 0x00 0x1000>;
			reg-names = "serdes\0siou";
			nvmem-cells = <0x11>;
			nvmem-cell-names = "soc_revision";
			resets = <0x12 0x10 0x12 0x3b 0x12 0x3c 0x12 0x3d 0x12 0x3e 0x12 0x3f 0x12 0x40 0x12 0x03 0x12 0x1d 0x12 0x1e 0x12 0x1f 0x12 0x20>;
			reset-names = "sata_rst\0usb0_crst\0usb1_crst\0usb0_hibrst\0usb1_hibrst\0usb0_apbrst\0usb1_apbrst\0dp_rst\0gem0_rst\0gem1_rst\0gem2_rst\0gem3_rst";
			phandle = <0x62>;

			lane0 {
				#phy-cells = <0x04>;
				phandle = <0x15>;
			};

			lane1 {
				#phy-cells = <0x04>;
				phandle = <0x14>;
			};

			lane2 {
				#phy-cells = <0x04>;
				phandle = <0x63>;
			};

			lane3 {
				#phy-cells = <0x04>;
				phandle = <0x64>;
			};
		};

		ahci@fd0c0000 {
			compatible = "ceva,ahci-1v84";
			status = "disabled";
			reg = <0x00 0xfd0c0000 0x00 0x2000>;
			interrupt-parent = <0x04>;
			interrupts = <0x00 0x85 0x04>;
			power-domains = <0x0c 0x1c>;
			#stream-id-cells = <0x04>;
			clocks = <0x03 0x16>;
			phandle = <0x65>;
		};

		mmc@ff160000 {
			u-boot,dm-pre-reloc;
			compatible = "xlnx,zynqmp-8.9a\0arasan,sdhci-8.9a";
			status = "disabled";
			interrupt-parent = <0x04>;
			interrupts = <0x00 0x30 0x04>;
			reg = <0x00 0xff160000 0x00 0x1000>;
			clock-names = "clk_xin\0clk_ahb";
			xlnx,device_id = <0x00>;
			#stream-id-cells = <0x01>;
			iommus = <0x0d 0x870>;
			power-domains = <0x0c 0x27>;
			nvmem-cells = <0x11>;
			nvmem-cell-names = "soc_revision";
			#clock-cells = <0x01>;
			clock-output-names = "clk_out_sd0\0clk_in_sd0";
			non-removable;
			disable-wp;
			bus-width = <0x08>;
			xlnx,mio-bank = <0x00>;
			clocks = <0x03 0x36 0x03 0x1f>;
			phandle = <0x66>;
		};

		mmc@ff170000 {
			u-boot,dm-pre-reloc;
			compatible = "xlnx,zynqmp-8.9a\0arasan,sdhci-8.9a";
			status = "disabled";
			interrupt-parent = <0x04>;
			interrupts = <0x00 0x31 0x04>;
			reg = <0x00 0xff170000 0x00 0x1000>;
			clock-names = "clk_xin\0clk_ahb";
			xlnx,device_id = <0x01>;
			#stream-id-cells = <0x01>;
			iommus = <0x0d 0x871>;
			power-domains = <0x0c 0x28>;
			nvmem-cells = <0x11>;
			nvmem-cell-names = "soc_revision";
			#clock-cells = <0x01>;
			clock-output-names = "clk_out_sd1\0clk_in_sd1";
			clocks = <0x03 0x37 0x03 0x1f>;
			clock-frequency = <0xb2cfe8b>;
			xlnx,mio-bank = <0x01>;
			phandle = <0x67>;
		};

		spi@ff040000 {
			compatible = "cdns,spi-r1p6";
			status = "disabled";
			interrupt-parent = <0x04>;
			interrupts = <0x00 0x13 0x04>;
			reg = <0x00 0xff040000 0x00 0x1000>;
			clock-names = "ref_clk\0pclk";
			#address-cells = <0x01>;
			#size-cells = <0x00>;
			power-domains = <0x0c 0x23>;
			clocks = <0x03 0x3a 0x03 0x1f>;
			phandle = <0x68>;
		};

		spi@ff050000 {
			compatible = "cdns,spi-r1p6";
			status = "okay";
			interrupt-parent = <0x04>;
			interrupts = <0x00 0x14 0x04>;
			reg = <0x00 0xff050000 0x00 0x1000>;
			clock-names = "ref_clk\0pclk";
			#address-cells = <0x01>;
			#size-cells = <0x00>;
			power-domains = <0x0c 0x24>;
			label = "TPM";
			num-cs = <0x01>;
			clocks = <0x03 0x3b 0x03 0x1f>;
			is-decoded-cs = <0x00>;
			phandle = <0x69>;

			tpm@0 {
				compatible = "infineon,slb9670\0tcg,tpm_tis-spi";
				reg = <0x00>;
				spi-max-frequency = <0x11a49a0>;
			};
		};

		timer@ff110000 {
			compatible = "cdns,ttc";
			status = "disabled";
			interrupt-parent = <0x04>;
			interrupts = <0x00 0x24 0x04 0x00 0x25 0x04 0x00 0x26 0x04>;
			reg = <0x00 0xff110000 0x00 0x1000>;
			timer-width = <0x20>;
			power-domains = <0x0c 0x18>;
			clocks = <0x03 0x1f>;
			phandle = <0x6a>;
		};

		timer@ff120000 {
			compatible = "cdns,ttc";
			status = "disabled";
			interrupt-parent = <0x04>;
			interrupts = <0x00 0x27 0x04 0x00 0x28 0x04 0x00 0x29 0x04>;
			reg = <0x00 0xff120000 0x00 0x1000>;
			timer-width = <0x20>;
			power-domains = <0x0c 0x19>;
			clocks = <0x03 0x1f>;
			phandle = <0x6b>;
		};

		timer@ff130000 {
			compatible = "cdns,ttc";
			status = "disabled";
			interrupt-parent = <0x04>;
			interrupts = <0x00 0x2a 0x04 0x00 0x2b 0x04 0x00 0x2c 0x04>;
			reg = <0x00 0xff130000 0x00 0x1000>;
			timer-width = <0x20>;
			power-domains = <0x0c 0x1a>;
			clocks = <0x03 0x1f>;
			phandle = <0x6c>;
		};

		timer@ff140000 {
			compatible = "cdns,ttc";
			status = "disabled";
			interrupt-parent = <0x04>;
			interrupts = <0x00 0x2d 0x04 0x00 0x2e 0x04 0x00 0x2f 0x04>;
			reg = <0x00 0xff140000 0x00 0x1000>;
			timer-width = <0x20>;
			power-domains = <0x0c 0x1b>;
			clocks = <0x03 0x1f>;
			phandle = <0x6d>;
		};

		serial@ff000000 {
			u-boot,dm-pre-reloc;
			compatible = "cdns,uart-r1p12\0xlnx,xuartps";
			status = "disabled";
			interrupt-parent = <0x04>;
			interrupts = <0x00 0x15 0x04>;
			reg = <0x00 0xff000000 0x00 0x1000>;
			clock-names = "uart_clk\0pclk";
			power-domains = <0x0c 0x21>;
			clocks = <0x03 0x38 0x03 0x1f>;
			phandle = <0x6e>;
		};

		serial@ff010000 {
			u-boot,dm-pre-reloc;
			compatible = "cdns,uart-r1p12\0xlnx,xuartps";
			status = "okay";
			interrupt-parent = <0x04>;
			interrupts = <0x00 0x16 0x04>;
			reg = <0x00 0xff010000 0x00 0x1000>;
			clock-names = "uart_clk\0pclk";
			power-domains = <0x0c 0x22>;
			clocks = <0x03 0x39 0x03 0x1f>;
			cts-override;
			device_type = "serial";
			port-number = <0x00>;
			phandle = <0x6f>;
		};

		usb0@ff9d0000 {
			#address-cells = <0x02>;
			#size-cells = <0x02>;
			status = "disabled";
			compatible = "xlnx,zynqmp-dwc3";
			reg = <0x00 0xff9d0000 0x00 0x100>;
			clock-names = "bus_clk\0ref_clk";
			power-domains = <0x0c 0x16>;
			ranges;
			nvmem-cells = <0x11>;
			nvmem-cell-names = "soc_revision";
			clocks = <0x03 0x20 0x03 0x22>;
			xlnx,tz-nonsecure = <0x01>;
			xlnx,usb-polarity = <0x00>;
			xlnx,usb-reset-mode = <0x00>;
			phandle = <0x70>;

			dwc3@fe200000 {
				compatible = "snps,dwc3";
				status = "disabled";
				reg = <0x00 0xfe200000 0x00 0x40000>;
				interrupt-parent = <0x04>;
				interrupt-names = "dwc_usb3\0otg\0hiber";
				interrupts = <0x00 0x41 0x04 0x00 0x45 0x04 0x00 0x4b 0x04>;
				#stream-id-cells = <0x01>;
				iommus = <0x0d 0x860>;
				snps,quirk-frame-length-adjustment = <0x20>;
				snps,refclk_fladj;
				snps,enable_guctl1_resume_quirk;
				snps,enable_guctl1_ipd_quirk;
				snps,xhci-stream-quirk;
				phandle = <0x71>;
			};
		};

		usb1@ff9e0000 {
			#address-cells = <0x02>;
			#size-cells = <0x02>;
			status = "disabled";
			compatible = "xlnx,zynqmp-dwc3";
			reg = <0x00 0xff9e0000 0x00 0x100>;
			clock-names = "bus_clk\0ref_clk";
			power-domains = <0x0c 0x17>;
			ranges;
			nvmem-cells = <0x11>;
			nvmem-cell-names = "soc_revision";
			clocks = <0x03 0x21 0x03 0x22>;
			phandle = <0x72>;

			dwc3@fe300000 {
				compatible = "snps,dwc3";
				status = "disabled";
				reg = <0x00 0xfe300000 0x00 0x40000>;
				interrupt-parent = <0x04>;
				interrupt-names = "dwc_usb3\0otg\0hiber";
				interrupts = <0x00 0x46 0x04 0x00 0x4a 0x04 0x00 0x4c 0x04>;
				#stream-id-cells = <0x01>;
				iommus = <0x0d 0x861>;
				snps,quirk-frame-length-adjustment = <0x20>;
				snps,refclk_fladj;
				snps,enable_guctl1_resume_quirk;
				snps,enable_guctl1_ipd_quirk;
				snps,xhci-stream-quirk;
				phandle = <0x73>;
			};
		};

		watchdog@fd4d0000 {
			compatible = "cdns,wdt-r1p2";
			status = "okay";
			interrupt-parent = <0x04>;
			interrupts = <0x00 0x71 0x01>;
			reg = <0x00 0xfd4d0000 0x00 0x1000>;
			timeout-sec = <0x3c>;
			reset-on-timeout;
			clocks = <0x03 0x4b>;
			phandle = <0x74>;
		};

		watchdog@ff150000 {
			compatible = "cdns,wdt-r1p2";
			status = "okay";
			interrupt-parent = <0x04>;
			interrupts = <0x00 0x34 0x01>;
			reg = <0x00 0xff150000 0x00 0x1000>;
			timeout-sec = <0x0a>;
			clocks = <0x03 0x70>;
			phandle = <0x75>;
		};

		ams@ffa50000 {
			compatible = "xlnx,zynqmp-ams";
			status = "okay";
			interrupt-parent = <0x04>;
			interrupts = <0x00 0x38 0x04>;
			interrupt-names = "ams-irq";
			reg = <0x00 0xffa50000 0x00 0x800>;
			reg-names = "ams-base";
			#address-cells = <0x02>;
			#size-cells = <0x02>;
			#io-channel-cells = <0x01>;
			ranges;
			clocks = <0x03 0x46>;
			phandle = <0x1a>;

			ams_ps@ffa50800 {
				compatible = "xlnx,zynqmp-ams-ps";
				status = "okay";
				reg = <0x00 0xffa50800 0x00 0x400>;
				phandle = <0x76>;
			};

			ams_pl@ffa50c00 {
				compatible = "xlnx,zynqmp-ams-pl";
				status = "okay";
				reg = <0x00 0xffa50c00 0x00 0x400>;
				phandle = <0x77>;
			};
		};

		dma@fd4c0000 {
			compatible = "xlnx,dpdma";
			status = "disabled";
			reg = <0x00 0xfd4c0000 0x00 0x1000>;
			interrupts = <0x00 0x7a 0x04>;
			interrupt-parent = <0x04>;
			clock-names = "axi_clk";
			power-domains = <0x0c 0x29>;
			dma-channels = <0x06>;
			#dma-cells = <0x01>;
			clocks = <0x03 0x14>;
			phandle = <0x16>;

			dma-video0channel {
				compatible = "xlnx,video0";
			};

			dma-video1channel {
				compatible = "xlnx,video1";
			};

			dma-video2channel {
				compatible = "xlnx,video2";
			};

			dma-graphicschannel {
				compatible = "xlnx,graphics";
			};

			dma-audio0channel {
				compatible = "xlnx,audio0";
			};

			dma-audio1channel {
				compatible = "xlnx,audio1";
			};
		};

		zynqmp-display@fd4a0000 {
			compatible = "xlnx,zynqmp-dpsub-1.7";
			status = "disabled";
			reg = <0x00 0xfd4a0000 0x00 0x1000 0x00 0xfd4aa000 0x00 0x1000 0x00 0xfd4ab000 0x00 0x1000 0x00 0xfd4ac000 0x00 0x1000>;
			reg-names = "dp\0blend\0av_buf\0aud";
			interrupts = <0x00 0x77 0x04>;
			interrupt-parent = <0x04>;
			clock-names = "dp_apb_clk\0dp_aud_clk\0dp_vtc_pixel_clk_in";
			power-domains = <0x0c 0x29>;
			clocks = <0x13 0x03 0x11 0x03 0x10>;
			phy-names = "dp-phy0\0dp-phy1";
			phys = <0x14 0x06 0x00 0x00 0x19bfcc0 0x15 0x06 0x01 0x00 0x19bfcc0>;
			xlnx,max-lanes = <0x02>;
			phandle = <0x78>;

			vid-layer {
				dma-names = "vid0\0vid1\0vid2";
				dmas = <0x16 0x00 0x16 0x01 0x16 0x02>;
				phandle = <0x79>;
			};

			gfx-layer {
				dma-names = "gfx0";
				dmas = <0x16 0x03>;
				phandle = <0x7a>;
			};

			i2c-bus {
			};

			zynqmp_dp_snd_codec0 {
				compatible = "xlnx,dp-snd-codec";
				clock-names = "aud_clk";
				clocks = <0x03 0x11>;
				status = "disabled";
				phandle = <0x19>;
			};

			zynqmp_dp_snd_pcm0 {
				compatible = "xlnx,dp-snd-pcm0";
				dmas = <0x16 0x04>;
				dma-names = "tx";
				status = "disabled";
				phandle = <0x17>;
			};

			zynqmp_dp_snd_pcm1 {
				compatible = "xlnx,dp-snd-pcm1";
				dmas = <0x16 0x05>;
				dma-names = "tx";
				status = "disabled";
				phandle = <0x18>;
			};

			zynqmp_dp_snd_card {
				compatible = "xlnx,dp-snd-card";
				xlnx,dp-snd-pcm = <0x17 0x18>;
				xlnx,dp-snd-codec = <0x19>;
				status = "disabled";
				phandle = <0x7b>;
			};
		};
	};

	aliases {
		gpio0 = "/amba/gpio@ff0a0000";
		i2c0 = "/amba/i2c@ff030000";
		i2c1 = "/amba/i2c@ff030000";
		mmc0 = "/amba/mmc@ff160000";
		mmc1 = "/amba/mmc@ff170000";
		rtc0 = "/amba/rtc@ffa60000";
		serial0 = "/amba/serial@ff010000";
		serial1 = "/amba/serial@ff010000";
		serial2 = "/dcc";
		spi0 = "/amba/spi@ff0f0000";
		spi1 = "/amba/spi@ff050000";
		spi2 = "/amba/spi@ff050000";
		usb0 = "/amba/usb0@ff9d0000";
		usb1 = "/amba/usb1@ff9e0000";
		nvmem0 = "/amba/i2c@ff030000/eeprom@50";
		nvmem1 = "/amba/i2c@ff030000/eeprom@51";
		ethernet0 = "/amba/ethernet@ff0e0000";
	};

	chosen {
		bootargs = "earlycon console=ttyPS0,115200 clk_ignore_unused ext4=/dev/mmcblk0p2:/rootfs init_fatal_sh=1 cma=1000M ";
		stdout-path = "serial0:115200n8";
	};

	gpio-keys {
		compatible = "gpio-keys";
		autorepeat;

		fwuen {
			label = "fwuen";
			gpios = <0x0e 0x0c 0x01>;
		};
	};

	leds {
		compatible = "gpio-leds";

		ds35 {
			label = "heartbeat";
			gpios = <0x0e 0x07 0x00>;
			linux,default-trigger = "heartbeat";
		};

		ds36 {
			label = "vbus_det";
			gpios = <0x0e 0x08 0x00>;
			default-state = "on";
		};
	};

	ams {
		compatible = "iio-hwmon";
		io-channels = <0x1a 0x00 0x1a 0x01 0x1a 0x02 0x1a 0x03 0x1a 0x04 0x1a 0x05 0x1a 0x06 0x1a 0x07 0x1a 0x08 0x1a 0x09 0x1a 0x0a 0x1a 0x0b 0x1a 0x0c 0x1a 0x0d 0x1a 0x0e 0x1a 0x0f 0x1a 0x10 0x1a 0x11 0x1a 0x12 0x1a 0x13 0x1a 0x14 0x1a 0x15 0x1a 0x16 0x1a 0x17 0x1a 0x18 0x1a 0x19 0x1a 0x1a 0x1a 0x1b 0x1a 0x1c 0x1a 0x1d>;
	};

	fclk0 {
		status = "okay";
		compatible = "xlnx,fclk";
		clocks = <0x03 0x47>;
		phandle = <0x7c>;
	};

	fclk1 {
		status = "okay";
		compatible = "xlnx,fclk";
		clocks = <0x03 0x48>;
		phandle = <0x7d>;
	};

	fclk2 {
		status = "okay";
		compatible = "xlnx,fclk";
		clocks = <0x03 0x49>;
		phandle = <0x7e>;
	};

	fclk3 {
		status = "okay";
		compatible = "xlnx,fclk";
		clocks = <0x03 0x4a>;
		phandle = <0x7f>;
	};

	pss_ref_clk {
		u-boot,dm-pre-reloc;
		compatible = "fixed-clock";
		#clock-cells = <0x00>;
		clock-frequency = <0x1fca055>;
		phandle = <0x06>;
	};

	video_clk {
		u-boot,dm-pre-reloc;
		compatible = "fixed-clock";
		#clock-cells = <0x00>;
		clock-frequency = <0x19bfcc0>;
		phandle = <0x07>;
	};

	pss_alt_ref_clk {
		u-boot,dm-pre-reloc;
		compatible = "fixed-clock";
		#clock-cells = <0x00>;
		clock-frequency = <0x00>;
		phandle = <0x08>;
	};

	gt_crx_ref_clk {
		u-boot,dm-pre-reloc;
		compatible = "fixed-clock";
		#clock-cells = <0x00>;
		clock-frequency = <0x66ff300>;
		phandle = <0x0a>;
	};

	aux_ref_clk {
		u-boot,dm-pre-reloc;
		compatible = "fixed-clock";
		#clock-cells = <0x00>;
		clock-frequency = <0x19bfcc0>;
		phandle = <0x09>;
	};

	dp_aclk {
		compatible = "fixed-clock";
		#clock-cells = <0x00>;
		clock-frequency = <0x5f5e100>;
		clock-accuracy = <0x64>;
		phandle = <0x13>;
	};

	memory {
		device_type = "memory";
		reg = <0x00 0x00 0x00 0x7ff00000 0x08 0x00 0x00 0x80000000>;
	};

	__symbols__ {
		cpu0 = "/cpus/cpu@0";
		cpu1 = "/cpus/cpu@1";
		cpu2 = "/cpus/cpu@2";
		cpu3 = "/cpus/cpu@3";
		CPU_SLEEP_0 = "/cpus/idle-states/cpu-sleep-0";
		cpu_opp_table = "/cpu-opp-table";
		ipi_mailbox_pmu1 = "/zynqmp_ipi/mailbox@ff990400";
		dcc = "/dcc";
		zynqmp_firmware = "/firmware/zynqmp-firmware";
		zynqmp_pcap = "/firmware/zynqmp-firmware/pcap";
		zynqmp_power = "/firmware/zynqmp-firmware/zynqmp-power";
		zynqmp_reset = "/firmware/zynqmp-firmware/reset-controller";
		pinctrl0 = "/firmware/zynqmp-firmware/pinctrl";
		zynqmp_clk = "/firmware/zynqmp-firmware/clock-controller";
		fpga_full = "/fpga-full";
		soc_revision = "/nvmem_firmware/soc_revision@0";
		efuse_dna = "/nvmem_firmware/efuse_dna@c";
		efuse_usr0 = "/nvmem_firmware/efuse_usr0@20";
		efuse_usr1 = "/nvmem_firmware/efuse_usr1@24";
		efuse_usr2 = "/nvmem_firmware/efuse_usr2@28";
		efuse_usr3 = "/nvmem_firmware/efuse_usr3@2c";
		efuse_usr4 = "/nvmem_firmware/efuse_usr4@30";
		efuse_usr5 = "/nvmem_firmware/efuse_usr5@34";
		efuse_usr6 = "/nvmem_firmware/efuse_usr6@38";
		efuse_usr7 = "/nvmem_firmware/efuse_usr7@3c";
		efuse_miscusr = "/nvmem_firmware/efuse_miscusr@40";
		efuse_chash = "/nvmem_firmware/efuse_chash@50";
		efuse_pufmisc = "/nvmem_firmware/efuse_pufmisc@54";
		efuse_sec = "/nvmem_firmware/efuse_sec@58";
		efuse_spkid = "/nvmem_firmware/efuse_spkid@5c";
		efuse_ppk0hash = "/nvmem_firmware/efuse_ppk0hash@a0";
		efuse_ppk1hash = "/nvmem_firmware/efuse_ppk1hash@d0";
		xlnx_rsa = "/zynqmp_rsa";
		xlnx_keccak_384 = "/sha384";
		xlnx_aes = "/zynqmp_aes";
		amba_apu = "/amba-apu@0";
		gic = "/amba-apu@0/interrupt-controller@f9010000";
		smmu = "/smmu@fd800000";
		amba = "/amba";
		can0 = "/amba/can@ff060000";
		can1 = "/amba/can@ff070000";
		cci = "/amba/cci@fd6e0000";
		fpd_dma_chan1 = "/amba/dma@fd500000";
		fpd_dma_chan2 = "/amba/dma@fd510000";
		fpd_dma_chan3 = "/amba/dma@fd520000";
		fpd_dma_chan4 = "/amba/dma@fd530000";
		fpd_dma_chan5 = "/amba/dma@fd540000";
		fpd_dma_chan6 = "/amba/dma@fd550000";
		fpd_dma_chan7 = "/amba/dma@fd560000";
		fpd_dma_chan8 = "/amba/dma@fd570000";
		gpu = "/amba/gpu@fd4b0000";
		lpd_dma_chan1 = "/amba/dma@ffa80000";
		lpd_dma_chan2 = "/amba/dma@ffa90000";
		lpd_dma_chan3 = "/amba/dma@ffaa0000";
		lpd_dma_chan4 = "/amba/dma@ffab0000";
		lpd_dma_chan5 = "/amba/dma@ffac0000";
		lpd_dma_chan6 = "/amba/dma@ffad0000";
		lpd_dma_chan7 = "/amba/dma@ffae0000";
		lpd_dma_chan8 = "/amba/dma@ffaf0000";
		mc = "/amba/memory-controller@fd070000";
		nand0 = "/amba/nand@ff100000";
		gem0 = "/amba/ethernet@ff0b0000";
		gem1 = "/amba/ethernet@ff0c0000";
		gem2 = "/amba/ethernet@ff0d0000";
		gem3 = "/amba/ethernet@ff0e0000";
		gpio = "/amba/gpio@ff0a0000";
		i2c0 = "/amba/i2c@ff020000";
		i2c1 = "/amba/i2c@ff030000";
		eeprom = "/amba/i2c@ff030000/eeprom@50";
		eeprom_cc = "/amba/i2c@ff030000/eeprom@51";
		da9131 = "/amba/i2c@ff030000/pmic@33";
		da9131_buck1 = "/amba/i2c@ff030000/pmic@33/regulators/buck1";
		da9131_buck2 = "/amba/i2c@ff030000/pmic@33/regulators/buck2";
		da9130 = "/amba/i2c@ff030000/pmic@32";
		da9130_buck1 = "/amba/i2c@ff030000/pmic@32/regulators/buck1";
		ocm = "/amba/memory-controller@ff960000";
		perf_monitor_ocm = "/amba/perf-monitor@ffa00000";
		perf_monitor_ddr = "/amba/perf-monitor@fd0b0000";
		perf_monitor_cci = "/amba/perf-monitor@fd490000";
		perf_monitor_lpd = "/amba/perf-monitor@ffa10000";
		pcie = "/amba/pcie@fd0e0000";
		pcie_intc = "/amba/pcie@fd0e0000/legacy-interrupt-controller";
		qspi = "/amba/spi@ff0f0000";
		rtc = "/amba/rtc@ffa60000";
		serdes = "/amba/zynqmp_phy@fd400000";
		lane0 = "/amba/zynqmp_phy@fd400000/lane0";
		lane1 = "/amba/zynqmp_phy@fd400000/lane1";
		lane2 = "/amba/zynqmp_phy@fd400000/lane2";
		lane3 = "/amba/zynqmp_phy@fd400000/lane3";
		sata = "/amba/ahci@fd0c0000";
		sdhci0 = "/amba/mmc@ff160000";
		sdhci1 = "/amba/mmc@ff170000";
		spi0 = "/amba/spi@ff040000";
		spi1 = "/amba/spi@ff050000";
		ttc0 = "/amba/timer@ff110000";
		ttc1 = "/amba/timer@ff120000";
		ttc2 = "/amba/timer@ff130000";
		ttc3 = "/amba/timer@ff140000";
		uart0 = "/amba/serial@ff000000";
		uart1 = "/amba/serial@ff010000";
		usb0 = "/amba/usb0@ff9d0000";
		dwc3_0 = "/amba/usb0@ff9d0000/dwc3@fe200000";
		usb1 = "/amba/usb1@ff9e0000";
		dwc3_1 = "/amba/usb1@ff9e0000/dwc3@fe300000";
		watchdog0 = "/amba/watchdog@fd4d0000";
		lpd_watchdog = "/amba/watchdog@ff150000";
		xilinx_ams = "/amba/ams@ffa50000";
		ams_ps = "/amba/ams@ffa50000/ams_ps@ffa50800";
		ams_pl = "/amba/ams@ffa50000/ams_pl@ffa50c00";
		xlnx_dpdma = "/amba/dma@fd4c0000";
		zynqmp_dpsub = "/amba/zynqmp-display@fd4a0000";
		vid_layer = "/amba/zynqmp-display@fd4a0000/vid-layer";
		gfx_layer = "/amba/zynqmp-display@fd4a0000/gfx-layer";
		zynqmp_dp_snd_codec0 = "/amba/zynqmp-display@fd4a0000/zynqmp_dp_snd_codec0";
		zynqmp_dp_snd_pcm0 = "/amba/zynqmp-display@fd4a0000/zynqmp_dp_snd_pcm0";
		zynqmp_dp_snd_pcm1 = "/amba/zynqmp-display@fd4a0000/zynqmp_dp_snd_pcm1";
		zynqmp_dp_snd_card0 = "/amba/zynqmp-display@fd4a0000/zynqmp_dp_snd_card";
		fclk0 = "/fclk0";
		fclk1 = "/fclk1";
		fclk2 = "/fclk2";
		fclk3 = "/fclk3";
		pss_ref_clk = "/pss_ref_clk";
		video_clk = "/video_clk";
		pss_alt_ref_clk = "/pss_alt_ref_clk";
		gt_crx_ref_clk = "/gt_crx_ref_clk";
		aux_ref_clk = "/aux_ref_clk";
		dp_aclk = "/dp_aclk";
	};
};
